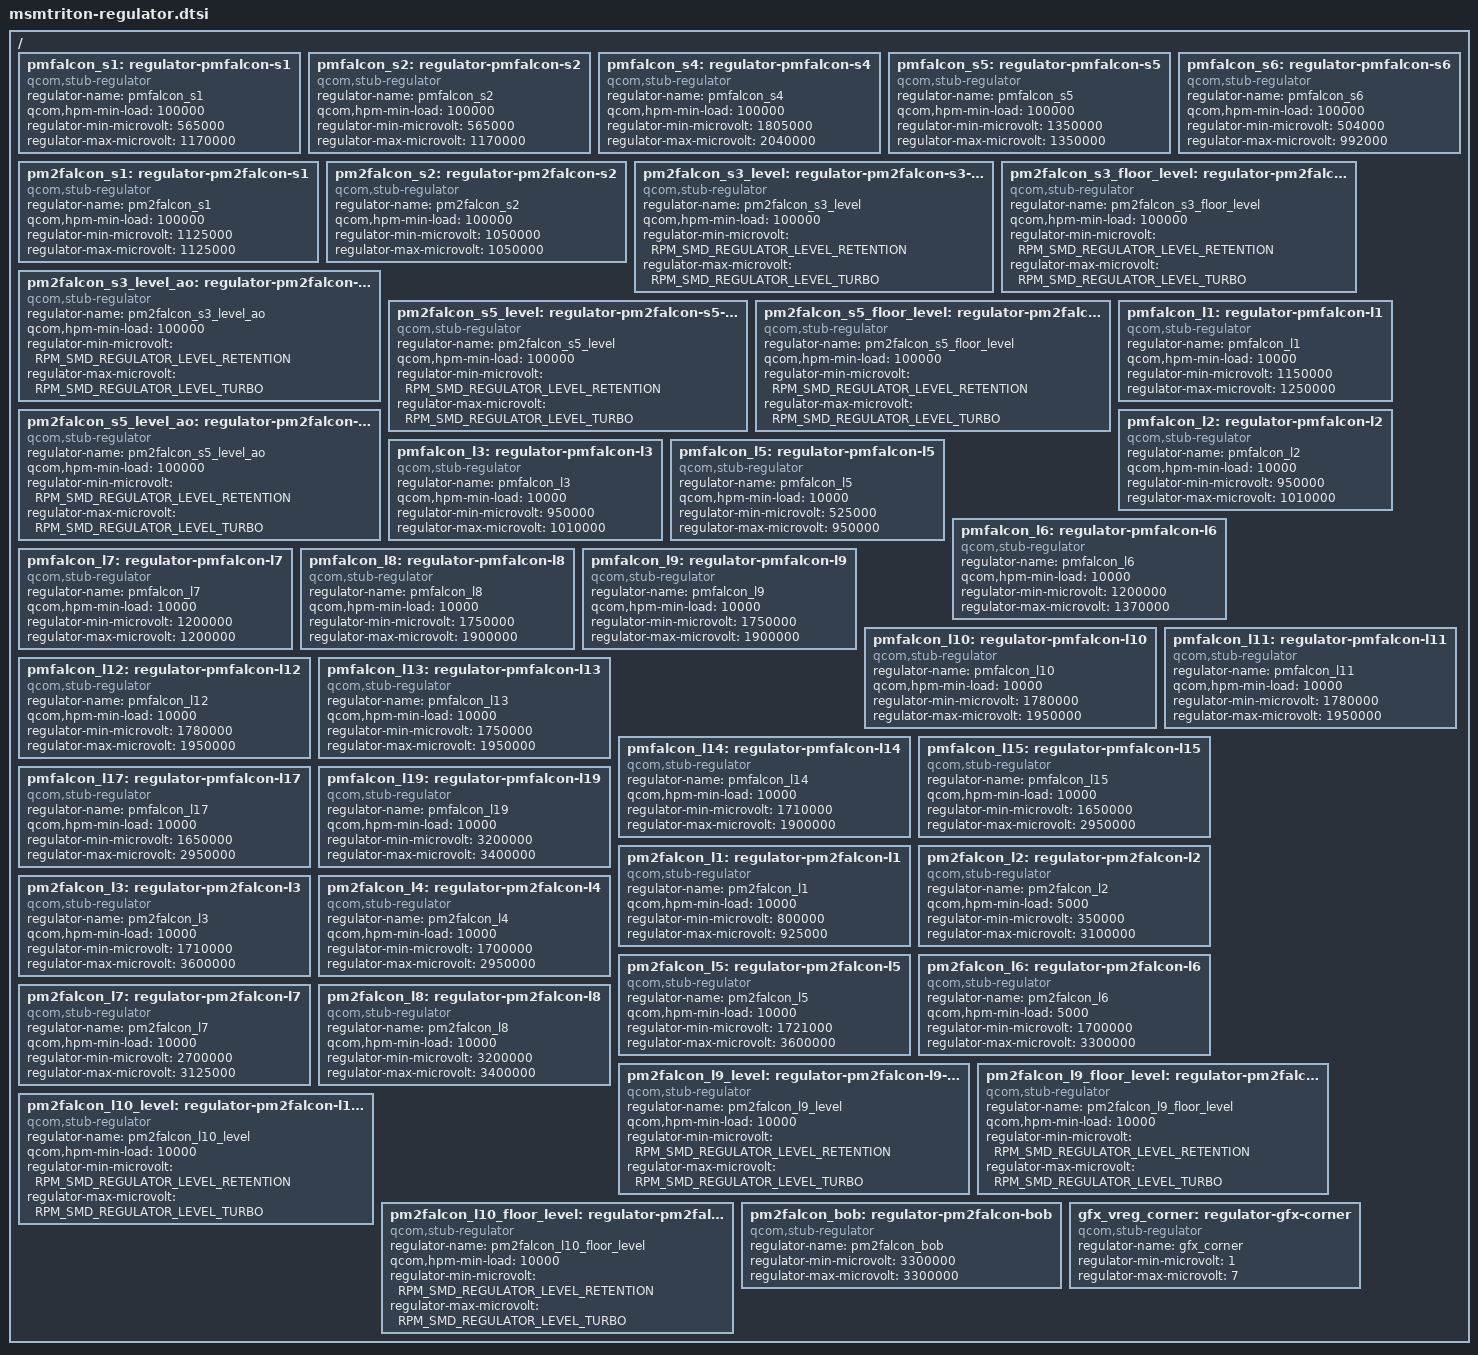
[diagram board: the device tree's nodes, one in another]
/* Copyright (c) 2016, The Linux Foundation. All rights reserved.
 *
 * This program is free software; you can redistribute it and/or modify
 * it under the terms of the GNU General Public License version 2 and
 * only version 2 as published by the Free Software Foundation.
 *
 * This program is distributed in the hope that it will be useful,
 * but WITHOUT ANY WARRANTY; without even the implied warranty of
 * MERCHANTABILITY or FITNESS FOR A PARTICULAR PURPOSE.  See the
 * GNU General Public License for more details.
 */

/* Stub regulators */

/ {
	/* PMFALCON S1 - VDD_APC0 supply */
	pmfalcon_s1: regulator-pmfalcon-s1 {
		compatible = "qcom,stub-regulator";
		regulator-name = "pmfalcon_s1";
		qcom,hpm-min-load = <100000>;
		regulator-min-microvolt = <565000>;
		regulator-max-microvolt = <1170000>;
	};

	/* PMFALCON S2 + S3 = VDD_APC1 supply */
	pmfalcon_s2: regulator-pmfalcon-s2 {
		compatible = "qcom,stub-regulator";
		regulator-name = "pmfalcon_s2";
		qcom,hpm-min-load = <100000>;
		regulator-min-microvolt = <565000>;
		regulator-max-microvolt = <1170000>;
	};

	pmfalcon_s4: regulator-pmfalcon-s4 {
		compatible = "qcom,stub-regulator";
		regulator-name = "pmfalcon_s4";
		qcom,hpm-min-load = <100000>;
		regulator-min-microvolt = <1805000>;
		regulator-max-microvolt = <2040000>;
	};

	pmfalcon_s5: regulator-pmfalcon-s5 {
		compatible = "qcom,stub-regulator";
		regulator-name = "pmfalcon_s5";
		qcom,hpm-min-load = <100000>;
		regulator-min-microvolt = <1350000>;
		regulator-max-microvolt = <1350000>;
	};

	pmfalcon_s6: regulator-pmfalcon-s6 {
		compatible = "qcom,stub-regulator";
		regulator-name = "pmfalcon_s6";
		qcom,hpm-min-load = <100000>;
		regulator-min-microvolt = <504000>;
		regulator-max-microvolt = <992000>;
	};

	pm2falcon_s1: regulator-pm2falcon-s1 {
		compatible = "qcom,stub-regulator";
		regulator-name = "pm2falcon_s1";
		qcom,hpm-min-load = <100000>;
		regulator-min-microvolt = <1125000>;
		regulator-max-microvolt = <1125000>;
	};

	pm2falcon_s2: regulator-pm2falcon-s2 {
		compatible = "qcom,stub-regulator";
		regulator-name = "pm2falcon_s2";
		qcom,hpm-min-load = <100000>;
		regulator-min-microvolt = <1050000>;
		regulator-max-microvolt = <1050000>;
	};

	/* PMFALCON S3 + S4 - VDD_CX supply */
	pm2falcon_s3_level: regulator-pm2falcon-s3-level {
		compatible = "qcom,stub-regulator";
		regulator-name = "pm2falcon_s3_level";
		qcom,hpm-min-load = <100000>;
		regulator-min-microvolt = <RPM_SMD_REGULATOR_LEVEL_RETENTION>;
		regulator-max-microvolt = <RPM_SMD_REGULATOR_LEVEL_TURBO>;
	};

	pm2falcon_s3_floor_level: regulator-pm2falcon-s3-floor-level {
		compatible = "qcom,stub-regulator";
		regulator-name = "pm2falcon_s3_floor_level";
		qcom,hpm-min-load = <100000>;
		regulator-min-microvolt = <RPM_SMD_REGULATOR_LEVEL_RETENTION>;
		regulator-max-microvolt = <RPM_SMD_REGULATOR_LEVEL_TURBO>;
	};

	pm2falcon_s3_level_ao: regulator-pm2falcon-s3-level-ao {
		compatible = "qcom,stub-regulator";
		regulator-name = "pm2falcon_s3_level_ao";
		qcom,hpm-min-load = <100000>;
		regulator-min-microvolt = <RPM_SMD_REGULATOR_LEVEL_RETENTION>;
		regulator-max-microvolt = <RPM_SMD_REGULATOR_LEVEL_TURBO>;
	};

	/* PMFALCON S5 - VDD_MX supply */
	pm2falcon_s5_level: regulator-pm2falcon-s5-level {
		compatible = "qcom,stub-regulator";
		regulator-name = "pm2falcon_s5_level";
		qcom,hpm-min-load = <100000>;
		regulator-min-microvolt = <RPM_SMD_REGULATOR_LEVEL_RETENTION>;
		regulator-max-microvolt = <RPM_SMD_REGULATOR_LEVEL_TURBO>;
	};

	pm2falcon_s5_floor_level: regulator-pm2falcon-s5-floor-level {
		compatible = "qcom,stub-regulator";
		regulator-name = "pm2falcon_s5_floor_level";
		qcom,hpm-min-load = <100000>;
		regulator-min-microvolt = <RPM_SMD_REGULATOR_LEVEL_RETENTION>;
		regulator-max-microvolt = <RPM_SMD_REGULATOR_LEVEL_TURBO>;
	};

	pm2falcon_s5_level_ao: regulator-pm2falcon-s5-level-ao {
		compatible = "qcom,stub-regulator";
		regulator-name = "pm2falcon_s5_level_ao";
		qcom,hpm-min-load = <100000>;
		regulator-min-microvolt = <RPM_SMD_REGULATOR_LEVEL_RETENTION>;
		regulator-max-microvolt = <RPM_SMD_REGULATOR_LEVEL_TURBO>;
	};

	pmfalcon_l1: regulator-pmfalcon-l1 {
		compatible = "qcom,stub-regulator";
		regulator-name = "pmfalcon_l1";
		qcom,hpm-min-load = <10000>;
		regulator-min-microvolt = <1150000>;
		regulator-max-microvolt = <1250000>;
	};

	pmfalcon_l2: regulator-pmfalcon-l2 {
		compatible = "qcom,stub-regulator";
		regulator-name = "pmfalcon_l2";
		qcom,hpm-min-load = <10000>;
		regulator-min-microvolt = <950000>;
		regulator-max-microvolt = <1010000>;
	};

	pmfalcon_l3: regulator-pmfalcon-l3 {
		compatible = "qcom,stub-regulator";
		regulator-name = "pmfalcon_l3";
		qcom,hpm-min-load = <10000>;
		regulator-min-microvolt = <950000>;
		regulator-max-microvolt = <1010000>;
	};

	/* TODO: remove if ADRASTEA CX/MX not voted from APPS */
	pmfalcon_l5: regulator-pmfalcon-l5 {
		compatible = "qcom,stub-regulator";
		regulator-name = "pmfalcon_l5";
		qcom,hpm-min-load = <10000>;
		regulator-min-microvolt = <525000>;
		regulator-max-microvolt = <950000>;
	};

	pmfalcon_l6: regulator-pmfalcon-l6 {
		compatible = "qcom,stub-regulator";
		regulator-name = "pmfalcon_l6";
		qcom,hpm-min-load = <10000>;
		regulator-min-microvolt = <1200000>;
		regulator-max-microvolt = <1370000>;
	};

	pmfalcon_l7: regulator-pmfalcon-l7 {
		compatible = "qcom,stub-regulator";
		regulator-name = "pmfalcon_l7";
		qcom,hpm-min-load = <10000>;
		regulator-min-microvolt = <1200000>;
		regulator-max-microvolt = <1200000>;
	};

	pmfalcon_l8: regulator-pmfalcon-l8 {
		compatible = "qcom,stub-regulator";
		regulator-name = "pmfalcon_l8";
		qcom,hpm-min-load = <10000>;
		regulator-min-microvolt = <1750000>;
		regulator-max-microvolt = <1900000>;
	};

	pmfalcon_l9: regulator-pmfalcon-l9 {
		compatible = "qcom,stub-regulator";
		regulator-name = "pmfalcon_l9";
		qcom,hpm-min-load = <10000>;
		regulator-min-microvolt = <1750000>;
		regulator-max-microvolt = <1900000>;
	};

	pmfalcon_l10: regulator-pmfalcon-l10 {
		compatible = "qcom,stub-regulator";
		regulator-name = "pmfalcon_l10";
		qcom,hpm-min-load = <10000>;
		regulator-min-microvolt = <1780000>;
		regulator-max-microvolt = <1950000>;
	};

	pmfalcon_l11: regulator-pmfalcon-l11 {
		compatible = "qcom,stub-regulator";
		regulator-name = "pmfalcon_l11";
		qcom,hpm-min-load = <10000>;
		regulator-min-microvolt = <1780000>;
		regulator-max-microvolt = <1950000>;
	};

	pmfalcon_l12: regulator-pmfalcon-l12 {
		compatible = "qcom,stub-regulator";
		regulator-name = "pmfalcon_l12";
		qcom,hpm-min-load = <10000>;
		regulator-min-microvolt = <1780000>;
		regulator-max-microvolt = <1950000>;
	};

	pmfalcon_l13: regulator-pmfalcon-l13 {
		compatible = "qcom,stub-regulator";
		regulator-name = "pmfalcon_l13";
		qcom,hpm-min-load = <10000>;
		regulator-min-microvolt = <1750000>;
		regulator-max-microvolt = <1950000>;
	};

	pmfalcon_l14: regulator-pmfalcon-l14 {
		compatible = "qcom,stub-regulator";
		regulator-name = "pmfalcon_l14";
		qcom,hpm-min-load = <10000>;
		regulator-min-microvolt = <1710000>;
		regulator-max-microvolt = <1900000>;
	};

	pmfalcon_l15: regulator-pmfalcon-l15 {
		compatible = "qcom,stub-regulator";
		regulator-name = "pmfalcon_l15";
		qcom,hpm-min-load = <10000>;
		regulator-min-microvolt = <1650000>;
		regulator-max-microvolt = <2950000>;
	};

	pmfalcon_l17: regulator-pmfalcon-l17 {
		compatible = "qcom,stub-regulator";
		regulator-name = "pmfalcon_l17";
		qcom,hpm-min-load = <10000>;
		regulator-min-microvolt = <1650000>;
		regulator-max-microvolt = <2950000>;
	};

	pmfalcon_l19: regulator-pmfalcon-l19 {
		compatible = "qcom,stub-regulator";
		regulator-name = "pmfalcon_l19";
		qcom,hpm-min-load = <10000>;
		regulator-min-microvolt = <3200000>;
		regulator-max-microvolt = <3400000>;
	};

	pm2falcon_l1: regulator-pm2falcon-l1 {
		compatible = "qcom,stub-regulator";
		regulator-name = "pm2falcon_l1";
		qcom,hpm-min-load = <10000>;
		regulator-min-microvolt = <800000>;
		regulator-max-microvolt = <925000>;
	};

	pm2falcon_l2: regulator-pm2falcon-l2 {
		compatible = "qcom,stub-regulator";
		regulator-name = "pm2falcon_l2";
		qcom,hpm-min-load = <5000>;
		regulator-min-microvolt = <350000>;
		regulator-max-microvolt = <3100000>;
	};

	pm2falcon_l3: regulator-pm2falcon-l3 {
		compatible = "qcom,stub-regulator";
		regulator-name = "pm2falcon_l3";
		qcom,hpm-min-load = <10000>;
		regulator-min-microvolt = <1710000>;
		regulator-max-microvolt = <3600000>;
	};

	pm2falcon_l4: regulator-pm2falcon-l4 {
		compatible = "qcom,stub-regulator";
		regulator-name = "pm2falcon_l4";
		qcom,hpm-min-load = <10000>;
		regulator-min-microvolt = <1700000>;
		regulator-max-microvolt = <2950000>;
	};

	pm2falcon_l5: regulator-pm2falcon-l5 {
		compatible = "qcom,stub-regulator";
		regulator-name = "pm2falcon_l5";
		qcom,hpm-min-load = <10000>;
		regulator-min-microvolt = <1721000>;
		regulator-max-microvolt = <3600000>;
	};

	pm2falcon_l6: regulator-pm2falcon-l6 {
		compatible = "qcom,stub-regulator";
		regulator-name = "pm2falcon_l6";
		qcom,hpm-min-load = <5000>;
		regulator-min-microvolt = <1700000>;
		regulator-max-microvolt = <3300000>;
	};

	pm2falcon_l7: regulator-pm2falcon-l7 {
		compatible = "qcom,stub-regulator";
		regulator-name = "pm2falcon_l7";
		qcom,hpm-min-load = <10000>;
		regulator-min-microvolt = <2700000>;
		regulator-max-microvolt = <3125000>;
	};

	pm2falcon_l8: regulator-pm2falcon-l8 {
		compatible = "qcom,stub-regulator";
		regulator-name = "pm2falcon_l8";
		qcom,hpm-min-load = <10000>;
		regulator-min-microvolt = <3200000>;
		regulator-max-microvolt = <3400000>;
	};

	/* PMFALCON L9 = VDD_SSC_CX supply */
	pm2falcon_l9_level: regulator-pm2falcon-l9-level {
		compatible = "qcom,stub-regulator";
		regulator-name = "pm2falcon_l9_level";
		qcom,hpm-min-load = <10000>;
		regulator-min-microvolt = <RPM_SMD_REGULATOR_LEVEL_RETENTION>;
		regulator-max-microvolt = <RPM_SMD_REGULATOR_LEVEL_TURBO>;
	};

	pm2falcon_l9_floor_level: regulator-pm2falcon-l9-floor-level {
		compatible = "qcom,stub-regulator";
		regulator-name = "pm2falcon_l9_floor_level";
		qcom,hpm-min-load = <10000>;
		regulator-min-microvolt = <RPM_SMD_REGULATOR_LEVEL_RETENTION>;
		regulator-max-microvolt = <RPM_SMD_REGULATOR_LEVEL_TURBO>;
	};

	/* PMFALCON L10 = VDD_SSC_MX supply */
	pm2falcon_l10_level: regulator-pm2falcon-l10-level {
		compatible = "qcom,stub-regulator";
		regulator-name = "pm2falcon_l10_level";
		qcom,hpm-min-load = <10000>;
		regulator-min-microvolt = <RPM_SMD_REGULATOR_LEVEL_RETENTION>;
		regulator-max-microvolt = <RPM_SMD_REGULATOR_LEVEL_TURBO>;
	};

	pm2falcon_l10_floor_level: regulator-pm2falcon-l10-floor-level {
		compatible = "qcom,stub-regulator";
		regulator-name = "pm2falcon_l10_floor_level";
		qcom,hpm-min-load = <10000>;
		regulator-min-microvolt = <RPM_SMD_REGULATOR_LEVEL_RETENTION>;
		regulator-max-microvolt = <RPM_SMD_REGULATOR_LEVEL_TURBO>;
	};

	pm2falcon_bob: regulator-pm2falcon-bob {
		compatible = "qcom,stub-regulator";
		regulator-name = "pm2falcon_bob";
		regulator-min-microvolt = <3300000>;
		regulator-max-microvolt = <3300000>;
	};

	/* GFX Supply */
	gfx_vreg_corner: regulator-gfx-corner {
		compatible = "qcom,stub-regulator";
		regulator-name = "gfx_corner";
		regulator-min-microvolt = <1>;
		regulator-max-microvolt = <7>;
	};
};
